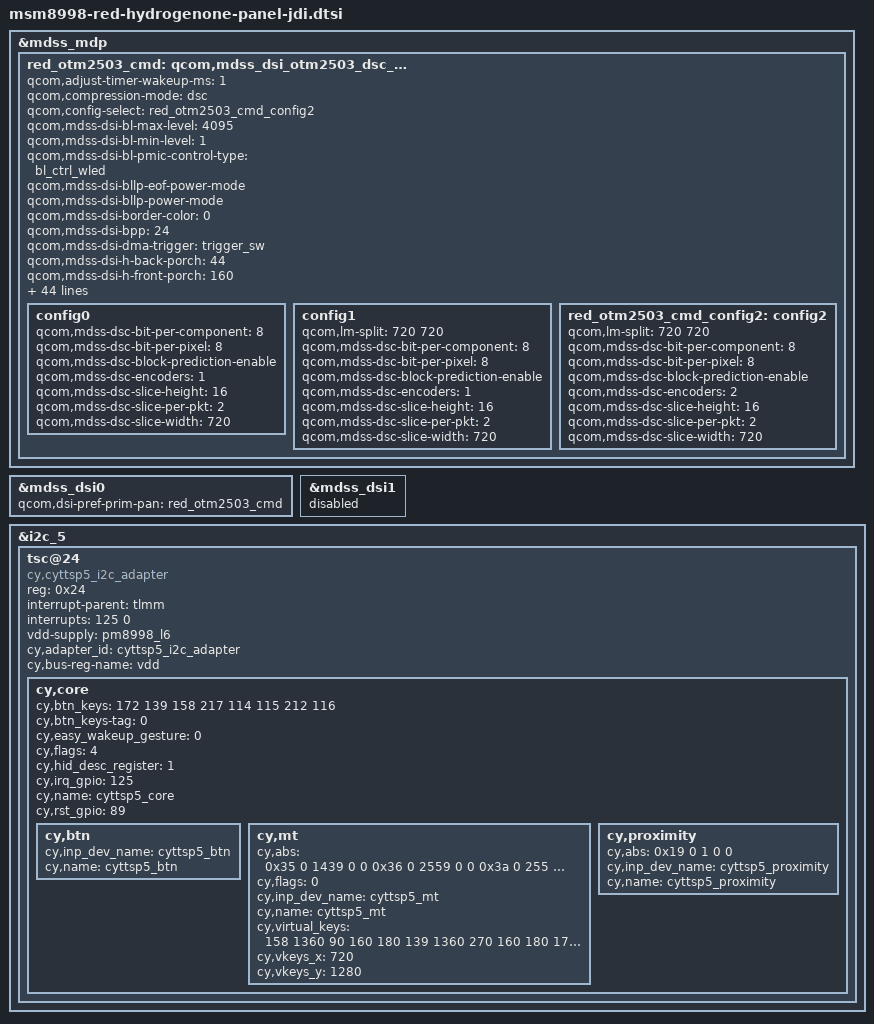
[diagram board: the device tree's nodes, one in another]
/*
 * Copyright (c) 2026, The LineageOS Project. All rights reserved.
 *
 * This program is free software; you can redistribute it and/or modify
 * it under the terms of the GNU General Public License version 2 and
 * only version 2 as published by the Free Software Foundation.
 */

/* JDI display and touch properties are isolated in this layer. */

&mdss_mdp {
	red_otm2503_cmd: qcom,mdss_dsi_otm2503_dsc_wqhd_cmd {
		qcom,adjust-timer-wakeup-ms = <1>;
		qcom,compression-mode = "dsc";
		qcom,config-select = <&red_otm2503_cmd_config2>;
		qcom,mdss-dsi-bl-max-level = <4095>;
		qcom,mdss-dsi-bl-min-level = <1>;
		qcom,mdss-dsi-bl-pmic-control-type = "bl_ctrl_wled";
		qcom,mdss-dsi-bllp-eof-power-mode;
		qcom,mdss-dsi-bllp-power-mode;
		qcom,mdss-dsi-border-color = <0>;
		qcom,mdss-dsi-bpp = <24>;
		qcom,mdss-dsi-dma-trigger = "trigger_sw";
		qcom,mdss-dsi-h-back-porch = <44>;
		qcom,mdss-dsi-h-front-porch = <160>;
		qcom,mdss-dsi-h-pulse-width = <16>;
		qcom,mdss-dsi-h-sync-pulse = <0>;
		qcom,mdss-dsi-h-sync-skew = <0>;
		qcom,mdss-dsi-lane-0-state;
		qcom,mdss-dsi-lane-1-state;
		qcom,mdss-dsi-lane-2-state;
		qcom,mdss-dsi-lane-3-state;
		qcom,mdss-dsi-mdp-trigger = "none";
		qcom,mdss-dsi-off-command =
			<0x05010000 0x0a000128 0x05010000 0x0a000110>;
		qcom,mdss-dsi-off-command-state = "dsi_hs_mode";
		qcom,mdss-dsi-on-command =
			[15 01 00 00 00 00 02 35 00
			 23 01 00 00 00 00 02 00 00
			 29 01 00 00 00 00 04 ff 25 03 01
			 23 01 00 00 00 00 02 00 80
			 29 01 00 00 00 00 03 ff 25 03
			 23 01 00 00 00 00 02 00 82
			 23 01 00 00 00 00 02 c4 01
			 23 01 00 00 00 00 02 00 00
			 29 01 00 00 00 00 04 ff 25 03 01
			 23 01 00 00 00 00 02 00 80
			 29 01 00 00 00 00 03 ff 25 03
			 23 01 00 00 00 00 02 00 00
			 23 01 00 00 00 00 02 1c 01
			 23 01 00 00 00 00 02 00 b0
			 29 01 00 00 00 00 10 b4 00 10 02 00 01 bb 00
			 0a 06 67 04 c5 10 f0 05
			 23 01 00 00 00 00 02 00 00
			 29 01 00 00 00 00 04 ff 00 00 00
			 05 01 00 00 78 00 01 11
			 39 01 00 00 00 00 01 2c
			 05 01 00 00 a0 00 01 29];
		qcom,mdss-dsi-on-command-state = "dsi_lp_mode";
		qcom,mdss-dsi-panel-blackness-level = <3000>;
		qcom,mdss-dsi-panel-framerate = <60>;
		qcom,mdss-dsi-panel-height = <2560>;
		qcom,mdss-dsi-panel-name = "OTM2503 cmd mode dsc dsi panel";
		qcom,mdss-dsi-panel-peak-brightness = <4500000>;
		qcom,mdss-dsi-panel-timings = <0x00170605 0x21200606 0x04030400>;
		qcom,mdss-dsi-panel-type = "dsi_cmd_mode";
		qcom,mdss-dsi-panel-width = <1440>;
		qcom,mdss-dsi-reset-sequence = <1 5 0 5 1 10>;
		qcom,mdss-dsi-stream = <0>;
		qcom,mdss-dsi-t-clk-post = <0x0b>;
		qcom,mdss-dsi-t-clk-pre = <0x26>;
		qcom,mdss-dsi-te-check-enable;
		qcom,mdss-dsi-te-dcs-command = <1>;
		qcom,mdss-dsi-te-pin-select = <1>;
		qcom,mdss-dsi-te-using-te-pin;
		qcom,mdss-dsi-traffic-mode = "burst_mode";
		qcom,mdss-dsi-v-back-porch = <7>;
		qcom,mdss-dsi-v-front-porch = <8>;
		qcom,mdss-dsi-v-pulse-width = <1>;
		qcom,mdss-dsi-virtual-channel-id = <0>;
		qcom,mdss-dsi-wr-mem-continue = <0x3c>;
		qcom,mdss-dsi-wr-mem-start = <0x2c>;
		qcom,mdss-pan-physical-height-dimension = <126>;
		qcom,mdss-pan-physical-width-dimension = <71>;
		qcom,panel-supply-entries = <&dsi_panel_pwr_supply>;
		qcom,ulps-enabled;

		config0 {
			qcom,mdss-dsc-bit-per-component = <8>;
			qcom,mdss-dsc-bit-per-pixel = <8>;
			qcom,mdss-dsc-block-prediction-enable;
			qcom,mdss-dsc-encoders = <1>;
			qcom,mdss-dsc-slice-height = <16>;
			qcom,mdss-dsc-slice-per-pkt = <2>;
			qcom,mdss-dsc-slice-width = <720>;
		};

		config1 {
			qcom,lm-split = <720 720>;
			qcom,mdss-dsc-bit-per-component = <8>;
			qcom,mdss-dsc-bit-per-pixel = <8>;
			qcom,mdss-dsc-block-prediction-enable;
			qcom,mdss-dsc-encoders = <1>;
			qcom,mdss-dsc-slice-height = <16>;
			qcom,mdss-dsc-slice-per-pkt = <2>;
			qcom,mdss-dsc-slice-width = <720>;
		};

		red_otm2503_cmd_config2: config2 {
			qcom,lm-split = <720 720>;
			qcom,mdss-dsc-bit-per-component = <8>;
			qcom,mdss-dsc-bit-per-pixel = <8>;
			qcom,mdss-dsc-block-prediction-enable;
			qcom,mdss-dsc-encoders = <2>;
			qcom,mdss-dsc-slice-height = <16>;
			qcom,mdss-dsc-slice-per-pkt = <2>;
			qcom,mdss-dsc-slice-width = <720>;
		};
	};
};

&mdss_dsi0 {
	qcom,dsi-pref-prim-pan = <&red_otm2503_cmd>;
	/delete-property/ qcom,panel-mode-gpio;
};

&mdss_dsi1 {
	status = "disabled";
};

&i2c_5 {
	status = "okay";
	/delete-node/ synaptics_dsx@70;

	tsc@24 {
		compatible = "cy,cyttsp5_i2c_adapter";
		reg = <0x24>;
		interrupt-parent = <&tlmm>;
		interrupts = <125 0>;
		vdd-supply = <&pm8998_l6>;
		cy,adapter_id = "cyttsp5_i2c_adapter";
		cy,bus-reg-name = "vdd";

		cy,core {
			cy,btn_keys = <172 139 158 217 114 115 212 116>;
			cy,btn_keys-tag = <0>;
			cy,easy_wakeup_gesture = <0>;
			cy,flags = <4>;
			cy,hid_desc_register = <1>;
			cy,irq_gpio = <125>;
			cy,name = "cyttsp5_core";
			cy,rst_gpio = <89>;

			cy,btn {
				cy,inp_dev_name = "cyttsp5_btn";
				cy,name = "cyttsp5_btn";
			};

			cy,mt {
				cy,abs = <0x35 0 1439 0 0
					0x36 0 2559 0 0
					0x3a 0 255 0 0
					0xffff 0 255 0 0
					0x39 0 15 0 0
					0x30 0 255 0 0
					0x31 0 255 0 0
					0x34 0xffffff81 127 0 0
					0x37 0 1 0 0
					0x3b 0 255 0 0>;
				cy,flags = <0>;
				cy,inp_dev_name = "cyttsp5_mt";
				cy,name = "cyttsp5_mt";
				cy,virtual_keys = <158 1360 90 160 180
					139 1360 270 160 180
					172 1360 450 160 180
					217 1360 630 160 180>;
				cy,vkeys_x = <720>;
				cy,vkeys_y = <1280>;
			};

			cy,proximity {
				cy,abs = <0x19 0 1 0 0>;
				cy,inp_dev_name = "cyttsp5_proximity";
				cy,name = "cyttsp5_proximity";
			};
		};
	};
};
